# UART_0 register map
Vendor: Texas Instruments
Peripheral module from a debugger description file (folder 66AK2G0x_66AK2G1x).
Registers are 32-bit, read-only, reset values left out (the file's numbers can be read two ways) unless marked. A register's access mark holds for its fields unless they carry their own. Offsets are as the file gives them; lines under a group give offsets from that group; [hi:lo] are bit positions; {n}, {i} and the like mark numbered series; 'fields as' and 'values as' point back to an identical list; <NAME> marks a mode.

## UART_0
0x00 UART_RBR
  [7:0] DATA — Received data
0x00 UART_THR
  [7:0] DATA — Data to transmit
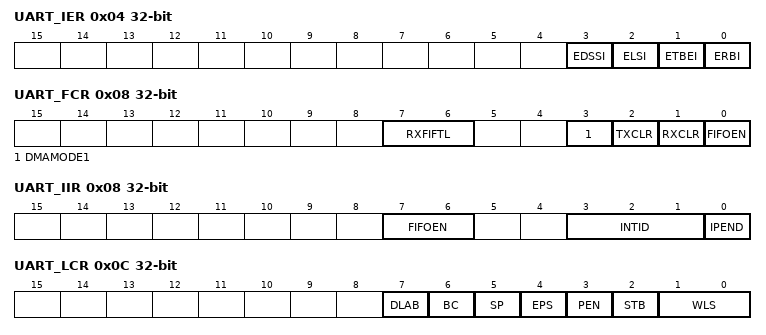
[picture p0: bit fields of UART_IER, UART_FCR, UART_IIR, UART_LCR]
0x04 UART_IER access per field
  [3] EDSSI rw — Modem status interrupt enable. 0 = Modem status interrupt is disabled. 1 = Modem status interrupt is enabled.
  [2] ELSI rw — Receiver line status interrupt enable. 0 = Receiver line status interrupt is disabled. 1 = Receiver line status interrupt is enabled.
  [1] ETBEI rw — Transmitter holding register empty interrupt enable. 0 = Transmitter holding register empty interrupt is disabled. 1 = Transmitter holding register empty interrupt is enabled.
  [0] ERBI rw — Receiver data available interrupt and character timeout indication interrupt enable. 0 = Receiver data available interrupt and character timeout indication interrupt is disabled. 1 = Receiver data available interrupt and character timeout indication interrupt is enabled.
0x08 UART_FCR access not given
  [7:6] RXFIFTL ro — Receiver FIFO trigger level. RXFIFTL sets the trigger level for the receiver FIFO. When the trigger level is reached, a receiver data-ready interrupt is generated (if the interrupt request is enabled). When the FIFO drops below the trigger level, the interrupt is cleared. 0h = 1 byte. 1h = 4 bytes. 2h = 8 bytes. 3h = 14 bytes.
  [3] DMAMODE1 wo — DMA MODE1 enable if FIFOs are enabled. 0 = DMA MODE1 is disabled. 1 = DMA MODE1 is enabled.
  [2] TXCLR — Transmitter FIFO clear. Write a 1 to TXCLR to clear the bit. 0 = No effect. 1 = Clears transmitter FIFO and resets the transmitter FIFO counter. The shift register is not cleared. (access W1toCl)
  [1] RXCLR — Receiver FIFO clear. Write a 1 to RXCLR to clear the bit. 0 = No effect. 1 = Clears receiver FIFO and resets the receiver FIFO counter. The shift register is not cleared. (access W1toCl)
  [0] FIFOEN wo — Transmitter and receiver FIFOs mode enable. FIFOEN must be set before other FCR bits are written to or the FCR bits are not programmed. Clearing this bit clears the FIFO counters. 0 = Non-FIFO mode. The transmitter and receiver FIFOs are disabled, and the FIFO pointers are cleared. 1 = FIFO mode. The transmitter and receiver FIFOs are enabled.
0x08 UART_IIR
  [7:6] FIFOEN — FIFOs enabled. 0h = Non-FIFO mode. 1h = Reserved. 2h = Reserved. 3h = FIFOs are enabled.
  [3:1] INTID — Interrupt type. See 0h = Modem status (priority 4, lowest). 1h = Transmitter holding register empty (priority 3). 2h = Receiver data available (priority 2). 3h = Receiver line status (priority 1, highest). 4h = Reserved. 5h = Reserved. 6h = Character timeout indication (priority 2). 7h = Reserved.
  [0] IPEND — Interrupt pending. When any UART interrupt is generated and is enabled in 0 = Interrupts pending. 1 = No interrupts pending.
0x0C UART_LCR access per field
  [7] DLAB rw — Divisor latch access bit. The divisor latch registers ( 0 = Allows access to the receiver buffer register ( 1 = Allows access to the divisor latches of the baud generator during a read or write operation (
  [6] BC rw — Break control. 0 = Break condition is disabled. 1 = Break condition is transmitted to the receiving UART. A break condition is a condition in which the TX signal is forced to the spacing (cleared) state.
  [5] SP rw — Stick parity. The SP bit works in conjunction with the EPS and PEN bits. The relationship between the SP, EPS, and PEN bits is summarized in 0 = Stick parity is disabled. 1 = Stick parity is enabled. When odd parity is selected (EPS = 0), the PARITY bit is transmitted and checked as set. When even parity is selected (EPS = 1), the PARITY bit is transmitted and checked as cleared.
  [4] EPS rw — Even parity select. Selects the parity when parity is enabled (PEN = 1). The EPS bit works in conjunction with the SP and PEN bits. The relationship between the SP, EPS, and PEN bits is summarized in 0 = Odd parity is selected (an odd number of logic 1s is transmitted or checked in the data and PARITY bits). 1 = Even parity is selected (an even number of logic 1s is transmitted or checked in the data and PARITY bits).
  [3] PEN rw — Parity enable. The PEN bit works in conjunction with the SP and EPS bits. The relationship between the SP, EPS, and PEN bits is summarized in 0 = No PARITY bit is transmitted or checked. 1 = Parity bit is generated in transmitted data and is checked in received data between the last data word bit and the first STOP bit.
  [2] STB rw — Number of STOP bits generated. STB specifies 1, 1.5, or 2 STOP bits in each transmitted character. When STB = 1, the WLS bit determines the number of STOP bits. The receiver clocks only the first STOP bit, regardless of the number of STOP bits selected. The number of STOP bits generated is summarized in 0 = One STOP bit is generated. 1 = WLS bit determines the number of STOP bits:
  [1:0] WLS rw — Word length select. Number of bits in each transmitted or received serial character. When STB = 1, the WLS bit determines the number of STOP bits. 0h = 5 bits 1h = 6 bits 2h = 7 bits 3h = 8 bits
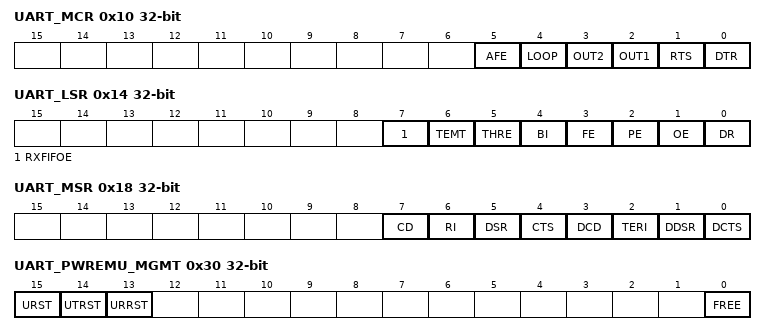
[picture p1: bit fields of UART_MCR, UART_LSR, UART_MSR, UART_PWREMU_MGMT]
0x10 UART_MCR access per field
  [5] AFE rw — Autoflow control enable. Autoflow control allows the RTS and CTS signals to provide handshaking between UARTs during data transfer. When AFE = 1, the RTS bit determines the autoflow control enabled. 0 = Autoflow control is disabled. 1 = Autoflow control is enabled:
  [4] LOOP rw — Loopback mode enable. LOOP is used for the diagnostic testing using the loopback feature. 0 = Loopback mode is disabled. 1 = Loopback mode is enabled. When LOOP is set, the following occur:
  [3] OUT2 rw — OUT2 Control Bit.
  [2] OUT1 rw — OUT1 Control Bit.
  [1] RTS rw — RTS control. When AFE = 1, the RTS bit determines the autoflow control enabled. 0 = RTS is disabled, only CTS is enabled. 1 = RTS and CTS are enabled.
  [0] DTR rw — Data terminal ready control bit.
0x14 UART_LSR
  [7] RXFIFOE — Receiver FIFO error. 0 = There has been no error, or RXFIFOE was cleared because the CPU read the erroneous character from the receiver buffer register ( 1 = There is a parity error, framing error, or break indicator in the receiver buffer register ( 0 = There has been no error, or RXFIFOE was cleared because the CPU read the erroneous character from the receiver FIFO and there are no more errors in the receiver FIFO. 1 = At least one parity error, framing error, or break indicator in the receiver FIFO.
  [6] TEMT — Transmitter empty (TEMT) indicator. 0 = Either the transmitter holding register ( 1 = Both the transmitter holding register ( 0 = Either the transmitter FIFO or the transmitter shift register (UART_TSR) contains a data character. 1 = Both the transmitter FIFO and the transmitter shift register (UART_TSR) are empty.
  [5] THRE — Transmitter holding register empty (THRE) indicator. If the THRE bit is set and the corresponding interrupt enable bit is set (ETBEI = 1 in 0 = Transmitter holding register ( 1 = Transmitter holding register ( 0 = Transmitter FIFO is not empty. At least one character has been written to the transmitter FIFO. The transmitter FIFO may be written to if it is not full. 1 = Transmitter FIFO is empty. The last character in the FIFO has been transferred to the transmitter shift register (UART_TSR).
  [4] BI — Break indicator. The BI bit is set whenever the receive data input (RX) was held low for longer than a fullword transmission time. A full-word transmission time is defined as the total time to transmit the START, data, PARITY, and STOP bits. If the BI bit is set and the corresponding interrupt enable bit is set (ELSI = 1 in 0 = No break has been detected, or the BI bit was cleared because the CPU read the erroneous character from the receiver buffer register ( 1 = A break has been detected with the character in the receiver buffer register ( 0 = No break has been detected, or the BI bit was cleared because the CPU read the erroneous character from the receiver FIFO and the next character to be read from the FIFO has no break indicator. 1 = A break has been detected with the character at the top of the receiver FIFO.
  [3] FE — Framing error (FE) indicator. A framing error occurs when the received character does not have a valid STOP bit. In response to a framing error, the UART sets the FE bit and waits until the signal on the RX pin goes high. When the RX signal goes high, the receiver is ready to detect a new START bit and receive new data. If the FE bit is set and the corresponding interrupt enable bit is set (ELSI = 1 in 0 = No framing error has been detected, or the FE bit was cleared because the CPU read the erroneous data from the receiver buffer register ( 1 = A framing error has been detected with the character in the receiver buffer register ( 0 = No framing error has been detected, or the FE bit was cleared because the CPU read the erroneous data from the receiver FIFO and the next character to be read from the FIFO has no framing error. 1 = A framing error has been detected with the character at the top of the receiver FIFO.
  [2] PE — Parity error (PE) indicator. A parity error occurs when the parity of the received character does not match the parity selected with the EPS bit in the line control register ( 0 = No parity error has been detected, or the PE bit was cleared because the CPU read the erroneous data from the receiver buffer register ( 1 = A parity error has been detected with the character in the receiver buffer register ( 0 = No parity error has been detected, or the PE bit was cleared because the CPU read the erroneous data from the receiver FIFO and the next character to be read from the FIFO has no parity error. 1 = A parity error has been detected with the character at the top of the receiver FIFO.
  [1] OE — Overrun error (OE) indicator. An overrun error in the non-FIFO mode is different from an overrun error in the FIFO mode. If the OE bit is set and the corresponding interrupt enable bit is set (ELSI = 1 in 0 = No overrun error has been detected, or the OE bit was cleared because the CPU read the content of the line status register ( 1 = Overrun error has been detected. Before the character in the receiver buffer register ( 0 = No overrun error has been detected, or the OE bit was cleared because the CPU read the content of the line status register ( 1 = Overrun error has been detected. If data continues to fill the FIFO beyond the trigger level, an overrun error occurs only after the FIFO is full and the next character has been completely received in the shift register. An overrun error is indicated to the CPU as soon as it happens. The new character overwrites the character in the shift register, but it is not transferred to the FIFO.
  [0] DR — Data-ready (DR) indicator for the receiver. If the DR bit is set and the corresponding interrupt enable bit is set (ERBI = 1 in 0 = Data is not ready, or the DR bit was cleared because the character was read from the receiver buffer register ( 1 = Data is ready. A complete incoming character has been received and transferred into the receiver buffer register ( 0 = Data is not ready, or the DR bit was cleared because all of the characters in the receiver FIFO have been read.. 1 = Data is ready. There is at least one unread character in the receiver FIFO. If the FIFO is empty, the DR bit is set as soon as a complete incoming character has been received and transferred into the FIFO. The DR bit remains set until the FIFO is empty again.
0x18 UART_MSR
  [7] CD — Complement of the Carrier Detect input. When the UART is in the diagnostic test mode (loopback mode
  [6] RI — Complement of the Ring Indicator input. When the UART is in the diagnostic test mode (loopback mode
  [5] DSR — Complement of the Data Set Ready input. When the UART is in the diagnostic test mode (loopback mode
  [4] CTS — Complement of the Clear To Send input. When the UART is in the diagnostic test mode (loopback mode
  [3] DCD — Change in DCD indicator bit. DCD indicates that the DCD input has changed state since the last time it was read by the CPU. When DCD is set and the modem status interrupt is enabled, a modem status interrupt is generated.
  [2] TERI — Trailing edge of RI (TERI) indicator bit. TERI indicates that the RI input has changed from a low to a high. When TERI is set and the modem status interrupt is enabled, a modem status interrupt is generated.
  [1] DDSR — Change in DSR indicator bit. DDSR indicates that the DSR input has changed state since the last time it was read by the CPU. When DDSR is set and the modem status interrupt is enabled, a modem status interrupt is generated.
  [0] DCTS — Change in CTS indicator bit. DCTS indicates that the CTS input has changed state since the last time it was read by the CPU. When DCTS is set (autoflow control is not enabled and the modem status interrupt is enabled), a modem status interrupt is generated. When autoflow control is enabled, no interrupt is generated.
0x1C UART_SCR
  [7:0] SCR — These bits are intended for the programmer's use as a scratch pad in the sense that it temporarily holds the programmer's data without affecting any other UART operation.
0x20 UART_DLL access per field
  [7:0] DLL rw — The 8 least-significant bits (LSBs) of the 16-bit divisor for generation of the baud clock in the baud rate generator.
0x24 UART_DLH access per field
  [7:0] DLH rw — The 8 most-significant bits (MSBs) of the 16-bit divisor for generation of the baud clock in the baud rate generator.
0x28 UART_PID
  [31:0] REV — TI internal data. Identifies revision of peripheral.
0x30 UART_PWREMU_MGMT access per field
  [15] URST rw — This bit resets and enables both the receiver and transmitter. If this bit is set, the UTRST and URRST are set automatically. 0 = The receiver and transmitter are disabled and in reset state. 1 = The receiver and transmitter are enabled.
  [14] UTRST rw — UART transmitter reset. Resets and enables the transmitter. 0 = Transmitter is disabled and in reset state. 1 = Transmitter is enabled.
  [13] URRST rw — UART receiver reset. Resets and enables the receiver. 0 = Receiver is disabled and in reset state. 1 = Receiver is enabled.
  [0] FREE rw — Free-running enable mode bit. This bit determines the emulation mode functionality of the UART. When halted, the UART can handle register read/write requests, but does not generate any transmission/reception, interrupts or events. 0 = If a transmission is not in progress, the UART halts immediately. If a transmission is in progress, the UART halts after completion of the one-word transmission. 1 = Free-running mode is enabled. UART continues to run normally.
0x34 UART_MDR access per field
  [0] OSM_SEL rw — Over-Sampling Mode Select. 0 = 16× oversampling. 1 = 13× oversampling.
